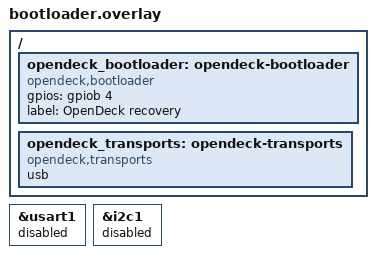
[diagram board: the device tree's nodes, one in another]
opendeck_uart_din_midi: &usart1 {};

/ {
    opendeck_bootloader: opendeck-bootloader {
        compatible = "opendeck,bootloader";
        gpios = <&gpiob 4 (GPIO_ACTIVE_HIGH | GPIO_PULL_DOWN)>;
        label = "OpenDeck recovery";
    };

    opendeck_transports: opendeck-transports {
        compatible = "opendeck,transports";
        usb;
    };
};

&usart1 {
    status = "disabled";
};

&i2c1 {
    status = "disabled";
};
